# ISS_IPIPE register map
Vendor: Texas Instruments
Peripheral module from a debugger description file (folder omap5430_ES2_PUBLIC).
Registers are 32-bit, access per field, reset 0x0 unless marked. A register's access mark holds for its fields unless they carry their own. Offsets are as the file gives them; lines under a group give offsets from that group; [hi:lo] are bit positions; {n}, {i} and the like mark numbered series; 'fields as' and 'values as' point back to an identical list; <NAME> marks a mode.

## ISS_IPIPE
0x00 IPIPE_SRC_EN — This register is not shadowed
  [0] EN rw — The start flag of the IPIPE module. When EN is 1, the IPIPE module starts a processing from the next rising edge of the VD. If the processing mode of the IPIPE module is one shot, the EN is cleared to 0 immediately after the processing has started.
    0=newEnum1 (waiting); 1=newEnum2 (start/busy)
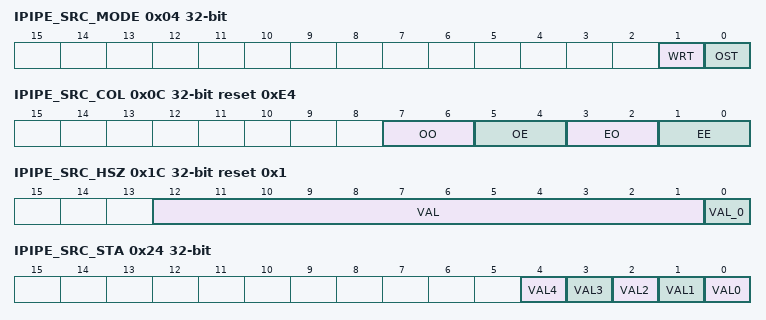
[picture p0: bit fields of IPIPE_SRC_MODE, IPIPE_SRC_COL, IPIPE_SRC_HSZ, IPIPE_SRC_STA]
0x04 IPIPE_SRC_MODE
  [1] WRT rw — The mode selection of the ipipeif_wrt which is an input port of the IPIPE module. If WRT is 0, the IPIPE module does not use the ipipeif_wrt. Else the IPIPE module uses it.
    0=newEnum1 (Disable); 1=newEnum2 (Enable)
  [0] OST rw — The processing mode selection of the IPIPE module. Value 0 indicates the mode of free run, value 1 indicates the mode of one shot.
    0=newEnum1 (Free run); 1=newEnum2 (One shot)
0x08 IPIPE_SRC_FMT
  [1:0] FMT rw — IPIPE module data path selection
    0=newEnum1 (IN: RAW BAYER OUT: YUV4:2:2 Note that the IPIPE YUV4:2:2 output goes to the RESIZER module where it can be further be converted in YUV4:2:0 or RGB format.); 1=newEnum2 (IN: RAW BAYER OUT: RAW BAYER The data are output after the White Balance module. It enables to bypass a large part of the IPIPE module.); 3=newEnum4 (IN: YUV4:2:2 OUT: YUV4:2:2 Note that the IPIPE YUV4:2:2 output goes to the RESIZER module where it can be further be converted in YUV4:2:0 or RGB format.); 2=newEnum3 (IN: RAW BAYER OUT: DISABLED The data are only going to BOXCAR and HISTOGRAM modules.)
0x0C IPIPE_SRC_COL reset 0xE4
  [all] fields
    0=newEnum1 (R); 1=newEnum2 (Gr); 3=newEnum4 (B); 2=newEnum3 (Gb)
  [7:6] OO rw — The color pattern of the odd line and odd pixel. This parameter is valid when IPIPE_SRC[FMT] is 0,1,2.
  [5:4] OE rw — The color pattern of the odd line and even pixel. This parameter is valid when IPIPE_SRC[FMT] is 0,1,2.
  [3:2] EO rw — The color pattern of the even line and odd pixel. This parameter is valid when IPIPE_SRC[FMT] is 0,1,2.
  [1:0] EE rw — The color pattern of the even line and even pixel. This parameter is valid when IPIPE_SRC[FMT] is 0,1,2.
0x10 IPIPE_SRC_VPS
  [15:0] VAL rw — The vertical position of the global frame from the rising edge of the VD. The IPIPE module will start an image processing from VAL line.
0x14 IPIPE_SRC_VSZ
  [12:0] VAL rw — The vertical size of the processing area. The VAL0 can not be written. The IPIPE module will process (VAL+1) lines.
0x18 IPIPE_SRC_HPS
  [15:0] VAL rw — The horizontal position of the global frame from the rising edge of the HD. The IPIPE module will start an image processing from VAL clock.
0x1C IPIPE_SRC_HSZ reset 0x1
  [12:1] VAL rw — The horizontal size of the processing area. The VAL0 is fixed. The IPIPE module processes (VAL+1) clocks.
  [0] VAL_0 ro — This is the LSB of the VAL[12:0]. This bit is read only.
0x20 IPIPE_SEL_SBU
  [0] EDOF rw — EDOF port selection This bit must not be enabled since the EDOF module is not implemented. This is a provision for a future revision of the IP.
    0=newEnum2 (Not used); 1=newEnum2 (Used)
0x24 IPIPE_SRC_STA ro — IPIPE STATUS REGISTER
  [4] VAL4 — Status of Histogram Process (busy status).
  [3] VAL3 — Status of Histogram bank select.
  [2] VAL2 — Status of BSC process (busy status).
  [1] VAL1 — Status of Boxcar process (busy status).
  [0] VAL0 — Status of Boxcar process (error status). This bit will be triggered when an overflow happens while transferring the boxcar data to memory. Instead of polling for this register, it is preferable to use the IPIPE_BOXCAR_OVF interrupt. Overflow errors are non recoverable at ISP level and require a software reset at ISS level.
0x28 IPIPE_GCK_MMR
  [0] REG rw — The on/off selection of the clk_arm_g0 which is used for some ARM register access.
    0=newEnum1 (Off); 1=newEnum2 (On)
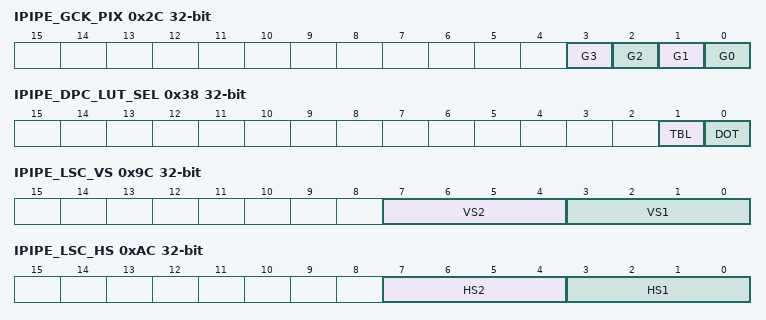
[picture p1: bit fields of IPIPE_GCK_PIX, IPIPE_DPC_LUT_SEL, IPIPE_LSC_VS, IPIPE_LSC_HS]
0x2C IPIPE_GCK_PIX — This register is not shadowed
  [all] fields
    0=newEnum1 (Disable); 1=newEnum2 (Enable)
  [3] G3 rw — The on/off selection of the clk_pix_g3 which is use for the IPIPE processes of EE .
  [2] G2 rw — The on/off selection of the clk_pix_g2 which is use for the IPIPE processes ofRGB2RGB blending to '422', 'Histogram(YCbCr input)'.
  [1] G1 rw — The on/off selection of the clk_pix_g1 which is used for the IPIPE processes of 'DefectCorrection' to 'WhiteBalance', and 'Histogram(RAW input)'.
  [0] G0 rw — The on/off selection of the clk_pix_g0 which is used for the IPIPE processing of 'Boxcar'.
0x34 IPIPE_DPC_LUT_EN
  [0] EN rw — Enable of LUT defect pixel correction.
    0=newEnum1 (Off); 1=newEnum2 (On)
0x38 IPIPE_DPC_LUT_SEL
  [1] TBL rw — LUT table type selection.
    0=newEnum1 (Up to 1024 entries. (use)); 1=newEnum2 (infinity number of entries. (not use))
  [0] DOT rw — Replace dot selection on processing method 0.
    0=newEnum1 (Replace with black dot); 1=newEnum2 (Replace with white dot)
0x3C IPIPE_DPC_LUT_ADR
  [9:0] ADR rw — The address of the first valid data in look-up-table
0x40 IPIPE_DPC_LUT_SIZ
  [9:0] SIZ rw — The number of valid data in look-up-table. (SIZ+1)
0x90 IPIPE_LSC_VOFT — LSC VOFT
  [12:0] LSC_VOFT rw
0x94 IPIPE_LSC_VA2
  [12:0] VAL rw — LSC VA2
0x98 IPIPE_LSC_VA1
  [12:0] VAL rw — LSC VA1
0x9C IPIPE_LSC_VS
  [7:4] VS2 rw — LSC VS1
  [3:0] VS1 rw — LSC VS1
0xA0 IPIPE_LSC_HOFT
  [12:0] VAL rw — LSC HOFT
0xA4 IPIPE_LSC_HA2
  [12:0] VAL rw — LSC HA2
0xA8 IPIPE_LSC_HA1
  [12:0] VAL rw — LSC HA1
0xAC IPIPE_LSC_HS
  [7:4] HS2 rw — LSC HS1
  [3:0] HS1 rw — LSC HS1
0xB0 IPIPE_LSC_GAN_R
  [7:0] VAL rw — GAN R
0xB4 IPIPE_LSC_GAN_GR
  [7:0] VAL rw — GAN GR
0xB8 IPIPE_LSC_GAN_GB
  [7:0] VAL rw — GAN GB
0xBC IPIPE_LSC_GAN_B
  [7:0] VAL rw — GAN B
0xC0 IPIPE_LSC_OFT_R
  [7:0] VAL rw — LSC OFT R
0xC4 IPIPE_LSC_OFT_GR
  [7:0] VAL rw — LSC OFT GR
0xC8 IPIPE_LSC_OFT_GB
  [7:0] VAL rw — LSC OFT GB
0xCC IPIPE_LSC_OFT_B
  [7:0] VAL rw — LSC OFT B
0xD0 IPIPE_LSC_SHF
  [3:0] VAL rw — LSC SHV
0xD4 IPIPE_LSC_MAX
  [8:0] VAL rw — LSC MAX
0x1D0 IPIPE_WB2_OFT_R — White Balance Register
  [11:0] VAL rw — Offset before white balance (S12) -2048 to +2047
0x1D4 IPIPE_WB2_OFT_GR — White Balance Register
  [11:0] VAL rw — Offset before white balance (S12) -2048 to +2047
0x1D8 IPIPE_WB2_OFT_GB — White Balance Register
  [11:0] VAL rw — Offset before white balance (S12) -2048 to +2047
0x1DC IPIPE_WB2_OFT_B — White Balance Register
  [11:0] VAL rw — Offset before white balance (S12) -2048 to +2047
0x1E0 IPIPE_WB2_WGN_R reset 0x200 — White Balance Register
  [12:0] VAL rw — White balance gain for R in U4.9 format 0 to +15.998
0x1E4 IPIPE_WB2_WGN_GR reset 0x200 — White Balance Register
  [12:0] VAL rw — White balance gain for Gr in U4.9 format 0 to +15.998
0x1E8 IPIPE_WB2_WGN_GB reset 0x200 — White Balance Register
  [12:0] VAL rw — White balance gain for Gb in U4.9 format 0 to +15.998
0x1EC IPIPE_WB2_WGN_B reset 0x200 — White Balance Register
  [12:0] VAL rw — White balance gain for B in U4.9 format 0 to +15.998
0x22C IPIPE_RGB1_MUL_RR reset 0x100 — RGB to RGB Conversion Register
  [11:0] VAL rw — The matrix coefficient. 011111111111 = 2047/256 = 7.99609375 011111111110 = 2046/256 [...] 000011111111 = 255/256 000100000000 = 256/256 = 1 000100000001 = 257/256 [...] 000000000001 = 1/256 000000000000 = 0/256 = 0 111111111111 = -1/256 = -0.00390625 111111111110 = -2/256 [...] 100000000001 = -2047/256 100000000000 = -2048/256 = -8.
0x230 IPIPE_RGB1_MUL_GR — RGB to RGB Conversion Register
  [11:0] VAL rw — The matrix coefficient.
0x234 IPIPE_RGB1_MUL_BR — RGB to RGB Conversion Register
  [11:0] VAL rw — The matrix coefficient.
0x238 IPIPE_RGB1_MUL_RG — RGB to RGB Conversion Register
  [11:0] VAL rw — The matrix coefficient.
0x23C IPIPE_RGB1_MUL_GG reset 0x100 — RGB to RGB Conversion Register
  [11:0] VAL rw — The matrix coefficient.
0x240 IPIPE_RGB1_MUL_BG — RGB to RGB Conversion Register
  [11:0] VAL rw — The matrix coefficient.
0x244 IPIPE_RGB1_MUL_RB — RGB to RGB Conversion Register
  [11:0] VAL rw — The matrix coefficient.
0x248 IPIPE_RGB1_MUL_GB — RGB to RGB Conversion Register
  [11:0] VAL rw — The matrix coefficient.
0x24C IPIPE_RGB1_MUL_BB reset 0x100 — RGB to RGB Conversion Register
  [11:0] VAL rw — The matrix coefficient.
0x250 IPIPE_RGB1_OFT_OR — RGB to RGB Conversion Register
  [12:0] VAL rw — The output offset value for R. (s13) -4096 to +4095
0x254 IPIPE_RGB1_OFT_OG — RGB to RGB Conversion Register
  [12:0] VAL rw — The output offset value for G. (s13) -4096 to +4095
0x258 IPIPE_RGB1_OFT_OB — RGB to RGB Conversion Register
  [12:0] VAL rw — The output offset value for B. (s13) -4096 to +4095
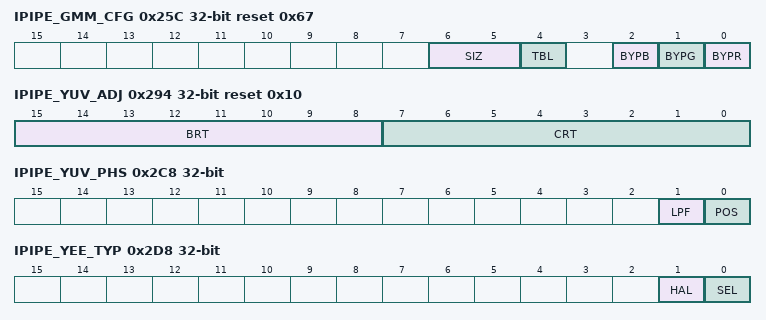
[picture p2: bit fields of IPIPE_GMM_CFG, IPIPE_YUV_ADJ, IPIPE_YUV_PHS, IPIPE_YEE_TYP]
0x25C IPIPE_GMM_CFG reset 0x67 — RGB to RGB Conversion Register
  [6:5] SIZ rw — The size of the gamma table.
    0=newEnum1 (64 words); 1=newEnum2 (128 words); 3=newEnum4 (512 words); 2=newEnum3 (256 words)
  [4] TBL rw — Selection of Gamma table.
    0=newEnum1 (RAM); 1=newEnum2 (ROM)
  [2] BYPB rw — Gamma correction mode for B
    0=newEnum2 (Not bypassed); 1=newEnum2 (Bypassed)
  [1] BYPG rw — Gamma correction mode for G
    0=newEnum2 (Not bypassed); 1=newEnum2 (Bypassed)
  [0] BYPR rw — Gamma correction mode for R
    0=newEnum2 (Not bypassed); 1=newEnum2 (Bypassed)
0x260 IPIPE_RGB2_MUL_RR reset 0x100 — RGB to RGB conversion after gamma
  [10:0] VAL rw — The matrix coefficient. 011111111111 = 2047/256 = 7.99609375 011111111110 = 2046/256 000011111111 = 255/256 000100000000 = 256/256 = 1 000100000001 = 257/256 000000000001 = 1/256 000000000000 = 0/256 = 0 111111111111 = -1/256 = -0.00390625 111111111110 = -2/256 100000000001 = -2047/256 100000000000 = -2048/256 = -8.
0x264 IPIPE_RGB2_MUL_GR — RGB to RGB conversion after gamma
  [10:0] VAL rw — The matrix coefficient.
0x268 IPIPE_RGB2_MUL_BR — RGB to RGB conversion after gamma
  [10:0] VAL rw — The matrix coefficient.
0x26C IPIPE_RGB2_MUL_RG — RGB to RGB conversion after gamma
  [10:0] VAL rw — The matrix coefficient.
0x270 IPIPE_RGB2_MUL_GG reset 0x100 — RGB to RGB conversion after gamma
  [10:0] VAL rw — The matrix coefficient.
0x274 IPIPE_RGB2_MUL_BG — RGB to RGB conversion after gamma
  [10:0] VAL rw — The matrix coefficient.
0x278 IPIPE_RGB2_MUL_RB — RGB to RGB conversion after gamma
  [10:0] VAL rw — The matrix coefficient.
0x27C IPIPE_RGB2_MUL_GB — RGB to RGB conversion after gamma
  [10:0] VAL rw — The matrix coefficient.
0x280 IPIPE_RGB2_MUL_BB reset 0x100 — RGB to RGB conversion after gamma
  [10:0] VAL rw — The matrix coefficient.
0x284 IPIPE_RGB2_OFT_OR — RGB to RGB conversion after gamma
  [10:0] VAL rw — The output offset value for R S10 number: -1024 to + 1023
0x288 IPIPE_RGB2_OFT_OG — RGB to RGB conversion after gamma
  [10:0] VAL rw — The output offset value for G S10 number: -1024 to + 1023
0x28C IPIPE_RGB2_OFT_OB — RGB to RGB conversion after gamma
  [10:0] VAL rw — The output offset value for B S10 number: -1024 to + 1023
0x294 IPIPE_YUV_ADJ reset 0x10 — RGB to YUV Conversion Register
  [15:8] BRT rw — The offset value for brightness control.
  [7:0] CRT rw — The multiplier coefficient value for contrast control. 00000000 = 0/16 = 0 00000001 = 1/16 00001111 = 15/16 00010000 = 16/16 = 1 00010001 = 17/16 11111110 = 254/16 11111111 = 255/16 = 15.9375
0x298 IPIPE_YUV_MUL_RY reset 0x4D — RGB to YUV Conversion Register
  [11:0] VAL rw — Matrix Coefficient for RY (S4.8 = -8 - +7.996)
0x29C IPIPE_YUV_MUL_GY reset 0x96 — RGB to YUV Conversion Register
  [11:0] VAL rw — Matrix Coefficient for GY (S4.8 = -8 - +7.996)
0x2A0 IPIPE_YUV_MUL_BY reset 0x1D — RGB to YUV Conversion Register
  [11:0] VAL rw — Matrix Coefficient for BY (S4.8 = -8 - +7.996)
0x2A4 IPIPE_YUV_MUL_RCB reset 0xFD5 — RGB to YUV Conversion Register
  [11:0] VAL rw — The matrix coefficient.
0x2A8 IPIPE_YUV_MUL_GCB reset 0xFAB — RGB to YUV Conversion Register
  [11:0] VAL rw — The matrix coefficient.
0x2AC IPIPE_YUV_MUL_BCB reset 0x80 — RGB to YUV Conversion Register
  [11:0] VAL rw — The matrix coefficient.
0x2B0 IPIPE_YUV_MUL_RCR reset 0x80 — RGB to YUV Conversion Register
  [11:0] VAL rw — The matrix coefficient.
0x2B4 IPIPE_YUV_MUL_GCR reset 0xF95 — RGB to YUV Conversion Register
  [11:0] VAL rw — The matrix coefficient.
0x2B8 IPIPE_YUV_MUL_BCR reset 0xFEB — RGB to YUV Conversion Register
  [11:0] VAL rw — The matrix coefficient.
0x2BC IPIPE_YUV_OFT_Y — RGB to YUV Conversion Register
  [10:0] VAL rw — The output offset value for Y
0x2C0 IPIPE_YUV_OFT_CB reset 0x80 — RGB to YUV Conversion Register
  [10:0] VAL rw — The output offset value for Cb For Cb/Cr, set (0x80 + offset value) here. (0x80 for zero offset.)
0x2C4 IPIPE_YUV_OFT_CR reset 0x80 — RGB to YUV Conversion Register
  [10:0] VAL rw — The output offset value for Cr For Cb/Cr, set (0x80 + offset value) here. (0x80 for zero offset.)
0x2C8 IPIPE_YUV_PHS — YUV4:2:2 down sampling register. This register controls the YUV4:4:4 to YUV4:2:2 chroma downsampling. This register is valid if .FMT = 0 (RAW input and YUV output). = 0 leads to pure subsampling, no filtering, cosited chroma output. = 1 leads to (1, 1) >> 1 filtering, centered chroma output. = 2 leads to (1, 2, 1) >> 1 filtering, cosited chroma output. = 3 leads to (1, 3, 3, 1) >> 3 filtering, centered chroma output. When the chroma output is cosited, and that downsampling is enabled in the RESIZER module, one need to take care that the averager disrupts the relative phase for luma and chroma color components. The and registers need to be used to fix the disruption.
  [1] LPF rw — 121-LPF enable for chrominance samples. This register is valid if IPIPE_SRC_FMT.FMT = 0 (RAW input and YUV output).
    0=newEnum1 (off); 1=newEnum2 (on)
  [0] POS rw — This bit sets the output position of the chrominance sample with regards to the luma sample positions. One can choose between centered and cosited. This register is valid if IPIPE_SRC_FMT.FMT = 0 (RAW input and YUV output). The RESIZER module does not change the relative position of the chroma samples vs. the luma samples between the input and output and the chroma position at the output of the IPIPE module and at the output of the RESIZER module must be identical. In other words, we must have RSZ_YUV_PHS.POS = IPIPE_YUV_PHS.POS.
    0=newEnum1 (Cosited = same position with luminance); 1=newEnum2 (Centered = middle of the luminance)
0x2D4 IPIPE_YEE_EN — Edge Enhancer Register
  [0] EN rw — The on/off selection of the Edge enhancer.
    0=newEnum1 (Disable); 1=newEnum2 (Enable)
0x2D8 IPIPE_YEE_TYP — Edge Enhancer Register
  [1] HAL rw — Halo reduction in Edge Sharpener module
  [0] SEL rw — Merging method between Edge Enhancer and Edge Sharpener
    0=newEnum1 (EE + ES); 1=newEnum2 (Maximum (EE, ES))
0x2DC IPIPE_YEE_SHF — Edge Enhancer Register
  [3:0] SHF rw — Down shift length of high pass filter (HPF) in edge enhancer.
0x2E0 IPIPE_YEE_MUL_00 — Edge Enhancer Register
  [9:0] VAL rw — Multiplier coefficient in HPF. 0111111111 = 511 0111111110 = 510 0000000001 = 1 0000000000 = 0 1111111111 = -1 1000000001 = -511 1000000000 = -512
0x2E4 IPIPE_YEE_MUL_01 — Edge Enhancer Register
  [9:0] VAL rw — Multiplier coefficient in HPF.
0x2E8 IPIPE_YEE_MUL_02 — Edge Enhancer Register
  [9:0] VAL rw — Multiplier coefficient in HPF.
{0x2C4+4i} IPIPE_YEE_MUL_{i} (i=10..12) — Edge Enhancer Register
  [9:0] VAL rw — Multiplier coefficient in HPF.
{0x2A8+4i} IPIPE_YEE_MUL_{i} (i=20..22) — Edge Enhancer Register
  [9:0] VAL rw — Multiplier coefficient in HPF.
0x304 IPIPE_YEE_THR — Edge Enhancer Register
  [5:0] VAL rw — Edge Enhancer lower threshold before referring to LUT. If HPF &lt;IPIPE_YEE_THR -&gt; output is HPF + IPIPE_YEE_THR If HPF &gt;IPIPE_YEE_THR -&gt; output is HPF - IPIPE_YEE_THR Otherwise, output is zero.
0x308 IPIPE_YEE_E_GAN — Edge Enhancer Register
  [11:0] VAL rw — Edge sharpener gain
0x30C IPIPE_YEE_E_THR_1 — Edge Enhancer Register
  [11:0] VAL rw — Edge sharpener HPF value lower limit
0x310 IPIPE_YEE_E_THR_2 — Edge Enhancer Register
  [5:0] VAL rw — Edge sharpener HPF value upper limit (after 6 bit right shift)
0x314 IPIPE_YEE_G_GAN — Edge Enhancer Register
  [7:0] VAL rw — Edge sharpener, gain value on gradient
0x318 IPIPE_YEE_G_OFT — Edge Enhancer Register
  [5:0] VAL rw — Edge sharpener, offset value on gradient
0x380 IPIPE_BOX_EN — Boxcar Register
  [0] EN rw — This bit enables or disables the BOXCAR functionality. The BOXCAR output is written to SDRAM. One need to set the IPIPE_BOX_SDR_SAD_H and IPIPE_BOX_SDR_SAD_L registers with the appropriate address.
    0=newEnum1 (Disable); 1=newEnum2 (Enable)
0x384 IPIPE_BOX_MODE — Boxcar Register
  [0] OST rw — The processing mode selection of the Boxcar function. A 0 indicates the mode of the free run, a 1 indicates the mode of the one shot.
    0=newEnum1 (Free run); 1=newEnum2 (One shot)
0x388 IPIPE_BOX_TYP — Boxcar Register
  [0] SEL rw — Block size in boxcar sampling
    0=newEnum1 (8x8); 1=newEnum2 (16x16)
0x38C IPIPE_BOX_SHF — Boxcar Register
  [2:0] VAL rw — The down shift value applied to the boxcar computation result. R out = SUM (Rij) &gt;&gt; SHF G out = (SUM (Gr ij)/2 + SUM (Gr ij)/2) &gt;&gt; SHF B out = SUM (Gij) &gt;&gt; SHF
0x390 IPIPE_BOX_SDR_SAD_H — Boxcar Register
  [15:0] VAL rw — The higher 11 bits of the first address of output in memory.
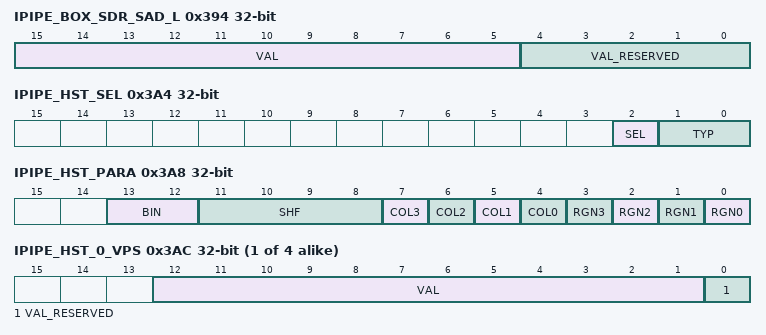
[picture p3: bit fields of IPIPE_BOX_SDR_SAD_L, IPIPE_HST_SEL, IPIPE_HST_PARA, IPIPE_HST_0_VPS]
0x394 IPIPE_BOX_SDR_SAD_L — Boxcar Register
  [15:5] VAL rw — The lower 16 bits of the first address of output in memory.
  [4:0] VAL_RESERVED ro — Ensures 32-byte alignment.
0x39C IPIPE_HST_EN — Histogram
  [0] EN rw — This bit enables or disables the HISTOGRAM functionality. When enabled, the HISTOGRAM computation will start the processing from the next rising edge of the VD pulse. If the processing mode of the HISTOGRAM is one shot, the enable bit will be cleared to 0 immediately after the processing has started.
    0=newEnum1 (disable); 1=newEnum2 (start/busy)
0x3A0 IPIPE_HST_MODE — Histogram
  [0] OST rw — The processing mode selection of the Histogram module. A 0 indicates the mode of the free run, a 1 indicates the mode of the one shot.
    0=newEnum1 (Free run); 1=newEnum2 (One shot)
0x3A4 IPIPE_HST_SEL — Histogram
  [2] SEL rw — Input selection. When SEL0=0, RGBY are sampled from the output of the line buffer in noise filter-2. When SEL0=1, YCbCr are sampled at the output of RGB2YCbCr module. Y is sampled twice.
    0=newEnum1 (From noise filter input); 1=newEnum2 (From RGBtoYUV)
  [1:0] TYP rw — G selection in Bayer mode (SEL0=0)
    0=newEnum1 (Gb); 1=newEnum2 (Gr); 3=newEnum4 (Reserved); 2=newEnum3 ((Gb+Gr)/2)
0x3A8 IPIPE_HST_PARA — Histogram COL0, COL1, COL2, and COL3 should be set to 1.
  [13:12] BIN rw — The number of the bins.
    0=newEnum1 (32); 1=newEnum2 (64); 3=newEnum4 (256); 2=newEnum3 (128)
  [11:8] SHF rw — The shift length of the input data. data = (INPUT &gt;&gt; SHF)
  [7] COL3 rw — The on/off selection of the color pattern 3 (Y).
    0=newEnum1 (Disable); 1=newEnum2 (Enable)
  [6] COL2 rw — The on/off selection of the color pattern 2 (B).
    0=newEnum1 (Disable); 1=newEnum2 (Enable)
  [5] COL1 rw — The on/off selection of the color pattern 1 (G).
    0=newEnum1 (Disable); 1=newEnum2 (Enable)
  [4] COL0 rw — The on/off selection of the color pattern 0 (R).
    0=newEnum1 (Disable); 1=newEnum2 (Enable)
  [n] RGN{n} rw (n=0..3) — The on/off selection of the region {n}.
    0=newEnum1 (Disable); 1=newEnum2 (Enable)
{0x3AC+0x10*i} IPIPE_HST_{i}_VPS (i=0..3) — Histogram
  [12:1] VAL rw — The vertical position of the region 0 from theIPIPE_SRC_VPS. The region {i} will start the Histogram processing from VAL line. VAL[0] can not be written.
  [0] VAL_RESERVED ro — The vertical position of the region 0 from theIPIPE_SRC_VPS. The region {i} will start the Histogram processing from VAL line. VAL[0] can not be written.
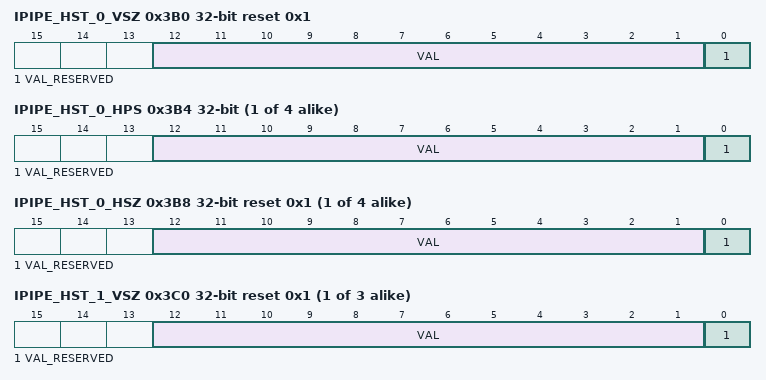
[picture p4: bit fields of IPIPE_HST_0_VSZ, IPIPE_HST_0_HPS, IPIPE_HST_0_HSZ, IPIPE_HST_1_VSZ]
0x3B0 IPIPE_HST_0_VSZ access not given reset 0x1 — Histogram
  [12:1] VAL rw — The vertical size of the region 0. The Histogram processing of the region 0 will process (VAL+1) lines.
  [0] VAL_RESERVED — The vertical size of the region 0. The Histogram processing of the region 0 will process (VAL+1) lines. VAL[0] cannot be written. (access R Rreturns1s)
{0x3B4+0x10*i} IPIPE_HST_{i}_HPS (i=0..3) — Histogram
  [12:1] VAL rw — The horizontal position of the region 0 from theIPIPE_SRC_HPS. The region {i} will start the Histogram processing from VAL clocks. VAL[0] can not be written.
  [0] VAL_RESERVED ro — The horizontal position of the region 0 from theIPIPE_SRC_HPS. The region {i} will start the Histogram processing from VAL clocks. VAL[0] can not be written.
{0x3B8+0x10*i} IPIPE_HST_{i}_HSZ access not given reset 0x1 (i=0..3) — Histogram
  [12:1] VAL rw — The horizontal size of the region {i}. The Histogram processing of the region {i} will process (VAL+1) clocks. VAL[0] cannot be written.
  [0] VAL_RESERVED — The horizontal size of the region {i}. The Histogram processing of the region {i} will process (VAL+1) clocks. VAL[0] cannot be written. (access R Rreturns1s)
{0x3B0+0x10*i} IPIPE_HST_{i}_VSZ access not given reset 0x1 (i=1..3) — Histogram
  [12:1] VAL rw — The vertical size of the region {i}. The Histogram processing of the region {i} will process (VAL+1) lines. VAL[0] cannot be written.
  [0] VAL_RESERVED — The vertical size of the region {i}. The Histogram processing of the region {i} will process (VAL+1) lines. VAL[0] cannot be written. (access R Rreturns1s)
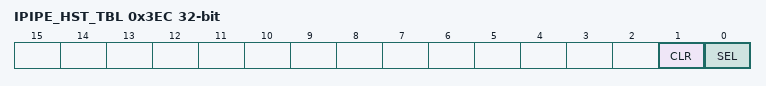
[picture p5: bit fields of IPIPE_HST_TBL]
0x3EC IPIPE_HST_TBL — Histogram
  [1] CLR rw — Histogram memory clear. The histogram can be cleared before the start of operations. However, the clear takes 512 cycles and therefore: + if line size &gt; 512, the first line must not be used for histogram computation. + if line size &lt; 512, ceil (512/line size) lines must not be used for histogram computation. It's the programmer's responsibility to set the histogram computation area outside the 'clear' area.
    0=newEnum1 (Disable); 1=newEnum2 (Enable)
  [0] SEL rw — This bit must be used to select which memory is used to store the histogram data. By selecting alternatively one or the other bit, one can double buffer the histogram output buffer. The 4-KiB memory can either be read by the CPU or a DMA request.
    0=newEnum1 (Use Table 0 and 1 = 4 KiB in the memory ISP map.); 1=newEnum2 (Use Table 2 and 3 = 4 KiB in the memory ISP map.)
0x3F0 IPIPE_HST_MUL_R — Histogram
  [7:0] GAIN rw
0x3F4 IPIPE_HST_MUL_GR — Histogram
  [7:0] GAIN rw
0x3F8 IPIPE_HST_MUL_GB — Histogram
  [7:0] GAIN rw
0x3FC IPIPE_HST_MUL_B — Histogram
  [7:0] GAIN rw
